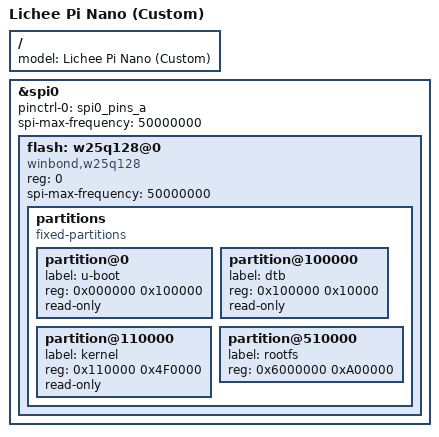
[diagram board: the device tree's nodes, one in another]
// SPDX-License-Identifier: (GPL-2.0+ OR X11)
// based on https://github.com/Lichee-Pi/linux/blob/nano-5.2-flash/arch/arm/boot/dts/suniv-f1c100s-licheepi-nano.dts on 2021-08
/*
 * Copyright 2024 Pato Diaz <padiazg@gmail.com>
 *                          <patricio@patodiaz.io>
 */

/dts-v1/;
#include "suniv-f1c100s-licheepi-nano.dts"

/ {
	model = "Lichee Pi Nano (Custom)";
};

&spi0 {
    pinctrl-names = "default";
    pinctrl-0 = <&spi0_pins_a>;
    status = "okay";
    spi-max-frequency = <50000000>;
    flash: w25q128@0 {
        #address-cells = <1>;
        #size-cells = <1>;
        compatible = "winbond,w25q128", "jedec,spi-nor";
        reg = <0>;
        spi-max-frequency = <50000000>;
        partitions {
            compatible = "fixed-partitions";
            #address-cells = <1>;
            #size-cells = <1>;

            partition@0 {
                label = "u-boot";
                reg = <0x000000 0x100000>;
                read-only;
            };

            partition@100000 {
                label = "dtb";
                reg = <0x100000 0x10000>;
                read-only;
            };

            partition@110000 {
                label = "kernel";
                reg = <0x110000 0x4F0000>;
                read-only;
            };

            partition@510000 {
                label = "rootfs";
                reg = <0x6000000 0xA00000>;
            };
        };
    };
};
